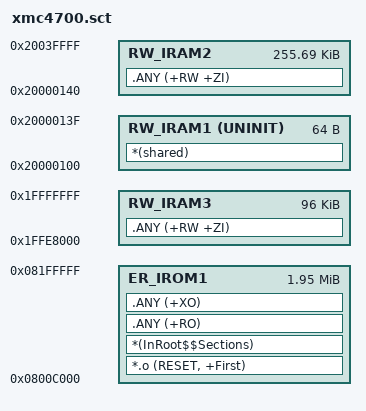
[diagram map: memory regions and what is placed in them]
; *************************************************************
; *** Scatter-Loading Description File generated by uVision ***
; *************************************************************

LR_IROM1 0x0800C000 0x001F4000  {    ; load region size_region
  ER_IROM1 0x0800C000 0x001F4000  {  ; load address = execution address
   *.o (RESET, +First)
   *(InRoot$$Sections)
   .ANY (+RO)
   .ANY (+XO)
  }
  
  ; Theoretically it should also be possible to place the shared parameters buffer at
  ; 0x20000000. Testing shows  though, that the first few bytes are still changed when
  ; the user program performs a software reset. Therefore it was moved forward by 0x100.
  RW_IRAM1 0x20000100 UNINIT 0x00000040  {  ; no init for shared params
   *(shared)
  }

  
  RW_IRAM2 0x20000140 0x0003FEC0  {  ; RW data
   .ANY (+RW +ZI)
  }
  
  RW_IRAM3 0x1FFE8000 0x00018000  {
   .ANY (+RW +ZI)
  }
}

